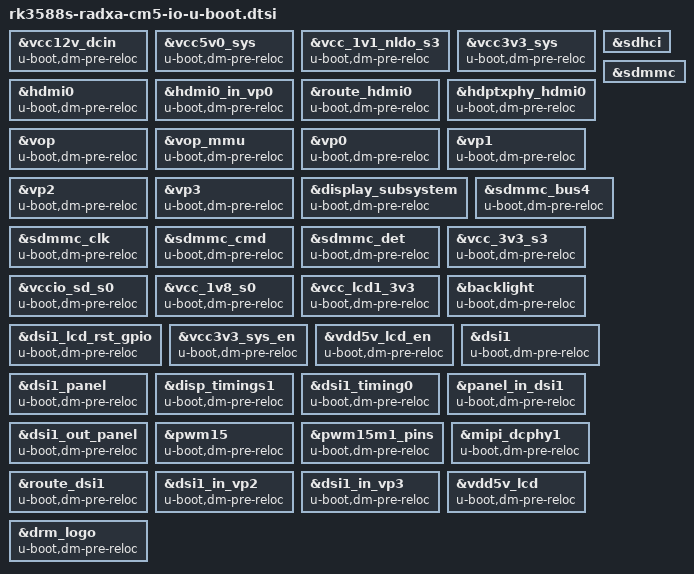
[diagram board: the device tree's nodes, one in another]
// SPDX-License-Identifier: (GPL-2.0+ OR MIT)
/*
 * Copyright (c) 2024 Rockchip Electronics Co., Ltd.
 * Copyright (c) 2024 Radxa Computer (Shenzhen) Co., Ltd.
 *
 */

#include "rk3588s-radxa-cm5-u-boot.dtsi"

&vcc12v_dcin {
	u-boot,dm-pre-reloc;
};

&vcc5v0_sys {
	u-boot,dm-pre-reloc;
};

&vcc_1v1_nldo_s3 {
	u-boot,dm-pre-reloc;
};

&vcc3v3_sys {
	u-boot,dm-pre-reloc;
};

&sdhci {
	u-boot,dm-spl;
};

&hdmi0 {
	u-boot,dm-pre-reloc;
};

&hdmi0_in_vp0 {
	u-boot,dm-pre-reloc;
};

&route_hdmi0 {
	u-boot,dm-pre-reloc;
};

&hdptxphy_hdmi0 {
	u-boot,dm-pre-reloc;
};

&vop {
	u-boot,dm-pre-reloc;
};

&vop_mmu {
	u-boot,dm-pre-reloc;
};

&vp0 {
	u-boot,dm-pre-reloc;
};

&vp1 {
	u-boot,dm-pre-reloc;
};

&vp2 {
	u-boot,dm-pre-reloc;
};

&vp3 {
	u-boot,dm-pre-reloc;
};

&display_subsystem {
	u-boot,dm-pre-reloc;
};

&hdptxphy_hdmi0 {
	u-boot,dm-pre-reloc;
};

&sdmmc {
	u-boot,dm-spl;
};

&sdmmc_bus4 {
	u-boot,dm-pre-reloc;
};

&sdmmc_clk {
	u-boot,dm-pre-reloc;
};

&sdmmc_cmd {
	u-boot,dm-pre-reloc;
};

&sdmmc_det {
	u-boot,dm-pre-reloc;
};

&vcc_3v3_s3 {
	u-boot,dm-pre-reloc;
};

&vccio_sd_s0 {
	u-boot,dm-pre-reloc;
};

&vcc_1v8_s0 {
	u-boot,dm-pre-reloc;
};

// 10 inch display
&vcc_lcd1_3v3 {
	u-boot,dm-pre-reloc;
};

&backlight {
	u-boot,dm-pre-reloc;
};

&dsi1_lcd_rst_gpio {
	u-boot,dm-pre-reloc;
};

&vcc3v3_sys_en {
	u-boot,dm-pre-reloc;
};

&vdd5v_lcd_en {
	u-boot,dm-pre-reloc;
};

&dsi1 {
	u-boot,dm-pre-reloc;
};

&dsi1_panel {
	u-boot,dm-pre-reloc;
};

&disp_timings1 {
	u-boot,dm-pre-reloc;
};

&dsi1_timing0 {
	u-boot,dm-pre-reloc;
};

&panel_in_dsi1 {
	u-boot,dm-pre-reloc;
};

&dsi1_out_panel {
	u-boot,dm-pre-reloc;
};

&pwm15 {
	u-boot,dm-pre-reloc;
};

&pwm15m1_pins {
	u-boot,dm-pre-reloc;
};

&mipi_dcphy1 {
	u-boot,dm-pre-reloc;
};

&route_dsi1 {
	u-boot,dm-pre-reloc;
};

&dsi1_in_vp2 {
	u-boot,dm-pre-reloc;
};

&dsi1_in_vp3 {
	u-boot,dm-pre-reloc;
};

&vdd5v_lcd {
	u-boot,dm-pre-reloc;
};

&drm_logo {
	u-boot,dm-pre-reloc;
};
